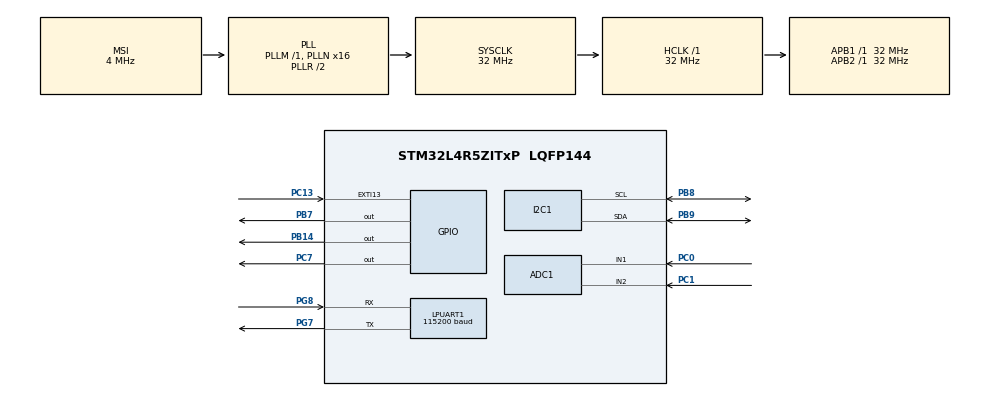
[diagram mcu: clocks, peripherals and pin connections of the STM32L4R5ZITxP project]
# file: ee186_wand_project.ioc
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ADC1.Channel-0\#ChannelRegularConversion=ADC_CHANNEL_1
ADC1.Channel-1\#ChannelRegularConversion=ADC_CHANNEL_2
ADC1.ContinuousConvMode=ENABLE
ADC1.DMAContinuousRequests=ENABLE
ADC1.NbrOfConversion=2
ADC1.NbrOfConversionFlag=1
ADC1.OffsetNumber-0\#ChannelRegularConversion=ADC_OFFSET_NONE
ADC1.OffsetNumber-1\#ChannelRegularConversion=ADC_OFFSET_NONE
ADC1.Rank-0\#ChannelRegularConversion=1
ADC1.Rank-1\#ChannelRegularConversion=2
ADC1.SamplingTime-0\#ChannelRegularConversion=ADC_SAMPLETIME_47CYCLES_5
ADC1.SamplingTime-1\#ChannelRegularConversion=ADC_SAMPLETIME_47CYCLES_5
ADC1.master=1
Dma.ADC1.0.Direction=DMA_PERIPH_TO_MEMORY
Dma.ADC1.0.EventEnable=DISABLE
Dma.ADC1.0.Instance=DMA1_Channel1
Dma.ADC1.0.MemDataAlignment=DMA_MDATAALIGN_HALFWORD
Dma.ADC1.0.MemInc=DMA_MINC_ENABLE
Dma.ADC1.0.Mode=DMA_CIRCULAR
Dma.ADC1.0.PeriphDataAlignment=DMA_PDATAALIGN_HALFWORD
Dma.ADC1.0.PeriphInc=DMA_PINC_DISABLE
Dma.ADC1.0.Polarity=HAL_DMAMUX_REQUEST_GEN_RISING
Dma.ADC1.0.Priority=DMA_PRIORITY_LOW
Dma.ADC1.0.RequestNumber=1
Dma.ADC1.0.SignalID=NONE
Dma.ADC1.0.SyncEnable=DISABLE
Dma.ADC1.0.SyncPolarity=HAL_DMAMUX_SYNC_NO_EVENT
Dma.ADC1.0.SyncRequestNumber=1
Dma.ADC1.0.SyncSignalID=NONE
Dma.Request0=ADC1
I2C1.Timing=0x00B07CB4
LPUART1.BaudRate=115200
LPUART1.WordLength=UART_WORDLENGTH_8B
Mcu.Family=STM32L4
Mcu.Name=STM32L4R5ZITxP
Mcu.Package=LQFP144
NVIC.DMA1_Channel1_IRQn=true\:0\:0\:false\:false\:true\:false\:true\:true
NVIC.EXTI15_10_IRQn=true\:0\:0\:true\:false\:true\:true\:true\:true
NVIC.PriorityGroup=NVIC_PRIORITYGROUP_4
NVIC.TIM4_IRQn=true\:0\:0\:false\:false\:true\:true\:true\:true
NVIC.TIM6_DAC_IRQn=true\:0\:0\:false\:false\:true\:true\:true\:true
PA13\ (JTMS/SWDIO).Mode=Serial_Wire
PA13\ (JTMS/SWDIO).Signal=SYS_JTMS-SWDIO
PA14\ (JTCK/SWCLK).Mode=Serial_Wire
PA14\ (JTCK/SWCLK).Signal=SYS_JTCK-SWCLK
PB14.Signal=GPIO_Output
PB7.Signal=GPIO_Output
PB8.Mode=I2C
PB8.Signal=I2C1_SCL
PB9.Mode=I2C
PB9.Signal=I2C1_SDA
PC0.Signal=ADCx_IN1
PC1.Signal=ADCx_IN2
PC13.Signal=GPXTI13
PC14-OSC32_IN\ (PC14).Mode=LSE-External-Oscillator
PC14-OSC32_IN\ (PC14).Signal=RCC_OSC32_IN
PC15-OSC32_OUT\ (PC15).Mode=LSE-External-Oscillator
PC15-OSC32_OUT\ (PC15).Signal=RCC_OSC32_OUT
PC7.Signal=GPIO_Output
PD14.Signal=S_TIM4_CH3
PD15.Signal=S_TIM4_CH4
PE0.Signal=S_TIM4_ETR
PG7.Mode=Asynchronous
PG7.Signal=LPUART1_TX
PG8.Mode=Asynchronous
PG8.Signal=LPUART1_RX
PH0-OSC_IN\ (PH0).Mode=HSE-External-Oscillator
PH0-OSC_IN\ (PH0).Signal=RCC_OSC_IN
PH1-OSC_OUT\ (PH1).Mode=HSE-External-Oscillator
PH1-OSC_OUT\ (PH1).Signal=RCC_OSC_OUT
ProjectManager.HeapSize=0x200
ProjectManager.StackSize=0x400
ProjectManager.TargetToolchain=STM32CubeIDE
RCC.ADCFreq_Value=48000000
RCC.AHBFreq_Value=32000000
RCC.APB1Freq_Value=32000000
RCC.APB1TimFreq_Value=32000000
RCC.APB2Freq_Value=32000000
RCC.APB2TimFreq_Value=32000000
RCC.CortexFreq_Value=32000000
RCC.HCLKFreq_Value=32000000
RCC.HSE_VALUE=8000000
RCC.HSI48_VALUE=48000000
RCC.HSI_VALUE=16000000
RCC.MSI_VALUE=4000000
RCC.PLLN=16
RCC.PLLSAI1N=24
RCC.SYSCLKFreq_VALUE=32000000
RCC.SYSCLKSource=RCC_SYSCLKSOURCE_PLLCLK
RCC.USBFreq_Value=48000000
RCC.VCOOutputFreq_Value=64000000
SH.ADCx_IN1.0=ADC1_IN1,IN1-Single-Ended
SH.ADCx_IN2.0=ADC1_IN2,IN2-Single-Ended
SH.S_TIM4_CH3.0=TIM4_CH3
SH.S_TIM4_CH4.0=TIM4_CH4
SH.S_TIM4_ETR.0=TIM4_ETR
TIM4.AutoReloadPreload=TIM_AUTORELOAD_PRELOAD_DISABLE
TIM4.Prescaler=31999
VP_TIM4_VS_ClockSourceINT.Mode=Internal
VP_TIM6_VS_ClockSourceINT.Mode=Enable_Timer
board=NUCLEO-L4R5ZI-P

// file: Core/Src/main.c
/* USER CODE BEGIN Header */
/**
  ******************************************************************************
  * @file           : main.c
  * @brief          : Main program body
  ******************************************************************************
  * @attention
  *
  * Copyright (c) 2026 STMicroelectronics.
  * All rights reserved.
  *
  * This software is licensed under terms that can be found in the LICENSE file
  * in the root directory of this software component.
  * If no LICENSE file comes with this software, it is provided AS-IS.
  *
  ******************************************************************************
  */
/* USER CODE END Header */
#include "main.h"

ADC_HandleTypeDef hadc1;
DMA_HandleTypeDef hdma_adc1;

I2C_HandleTypeDef hi2c1;

UART_HandleTypeDef hlpuart1;

TIM_HandleTypeDef htim4;
TIM_HandleTypeDef htim6;

void SystemClock_Config(void);
static void MX_GPIO_Init(void);
static void MX_DMA_Init(void);
static void MX_ADC1_Init(void);
static void MX_I2C1_Init(void);
static void MX_LPUART1_UART_Init(void);
static void MX_TIM4_Init(void);
static void MX_TIM6_Init(void);

int main(void)
{

  /* MCU Configuration--------------------------------------------------------*/

  /* Reset of all peripherals, Initializes the Flash interface and the Systick. */
  HAL_Init();

  /* Configure the system clock */
  SystemClock_Config();

  /* Initialize all configured peripherals */
  MX_GPIO_Init();
  MX_DMA_Init();
  MX_ADC1_Init();
  MX_I2C1_Init();
  MX_LPUART1_UART_Init();
  MX_TIM4_Init();
  MX_TIM6_Init();
  /* USER CODE BEGIN 2 */
  HAL_TIM_Base_Start_IT(&htim4); // start tim4 interrupt

  /* USER CODE END 2 */

  /* Infinite loop */
  while (1)
  {

  }
}

void SystemClock_Config(void)
{
  RCC_OscInitTypeDef RCC_OscInitStruct = {0};
  RCC_ClkInitTypeDef RCC_ClkInitStruct = {0};

  /** Configure the main internal regulator output voltage
  */
  if (HAL_PWREx_ControlVoltageScaling(PWR_REGULATOR_VOLTAGE_SCALE1) != HAL_OK)
  {
    Error_Handler();
  }

  /** Initializes the RCC Oscillators according to the specified parameters
  * in the RCC_OscInitTypeDef structure.
  */
  RCC_OscInitStruct.OscillatorType = RCC_OSCILLATORTYPE_MSI;
  RCC_OscInitStruct.MSIState = RCC_MSI_ON;
  RCC_OscInitStruct.MSICalibrationValue = 0;
  RCC_OscInitStruct.MSIClockRange = RCC_MSIRANGE_6;
  RCC_OscInitStruct.PLL.PLLState = RCC_PLL_ON;
  RCC_OscInitStruct.PLL.PLLSource = RCC_PLLSOURCE_MSI;
  RCC_OscInitStruct.PLL.PLLM = 1;
  RCC_OscInitStruct.PLL.PLLN = 16;
  RCC_OscInitStruct.PLL.PLLP = RCC_PLLP_DIV2;
  RCC_OscInitStruct.PLL.PLLQ = RCC_PLLQ_DIV2;
  RCC_OscInitStruct.PLL.PLLR = RCC_PLLR_DIV2;
  if (HAL_RCC_OscConfig(&RCC_OscInitStruct) != HAL_OK)
  {
    Error_Handler();
  }

  /** Initializes the CPU, AHB and APB buses clocks
  */
  RCC_ClkInitStruct.ClockType = RCC_CLOCKTYPE_HCLK|RCC_CLOCKTYPE_SYSCLK
                              |RCC_CLOCKTYPE_PCLK1|RCC_CLOCKTYPE_PCLK2;
  RCC_ClkInitStruct.SYSCLKSource = RCC_SYSCLKSOURCE_PLLCLK;
  RCC_ClkInitStruct.AHBCLKDivider = RCC_SYSCLK_DIV1;
  RCC_ClkInitStruct.APB1CLKDivider = RCC_HCLK_DIV1;
  RCC_ClkInitStruct.APB2CLKDivider = RCC_HCLK_DIV1;

  if (HAL_RCC_ClockConfig(&RCC_ClkInitStruct, FLASH_LATENCY_1) != HAL_OK)
  {
    Error_Handler();
  }
}

static void MX_ADC1_Init(void)
{

  ADC_ChannelConfTypeDef sConfig = {0};

  /** Common config
  */
  hadc1.Instance = ADC1;
  hadc1.Init.ClockPrescaler = ADC_CLOCK_ASYNC_DIV1;
  hadc1.Init.Resolution = ADC_RESOLUTION_12B;
  hadc1.Init.DataAlign = ADC_DATAALIGN_RIGHT;
  hadc1.Init.ScanConvMode = ADC_SCAN_ENABLE;
  hadc1.Init.EOCSelection = ADC_EOC_SINGLE_CONV;
  hadc1.Init.LowPowerAutoWait = DISABLE;
  hadc1.Init.ContinuousConvMode = ENABLE;
  hadc1.Init.NbrOfConversion = 2;
  hadc1.Init.DiscontinuousConvMode = DISABLE;
  hadc1.Init.ExternalTrigConv = ADC_SOFTWARE_START;
  hadc1.Init.ExternalTrigConvEdge = ADC_EXTERNALTRIGCONVEDGE_NONE;
  hadc1.Init.DMAContinuousRequests = ENABLE;
  hadc1.Init.Overrun = ADC_OVR_DATA_PRESERVED;
  hadc1.Init.OversamplingMode = DISABLE;
  if (HAL_ADC_Init(&hadc1) != HAL_OK)
  {
    Error_Handler();
  }

  /** Configure Regular Channel
  */
  sConfig.Channel = ADC_CHANNEL_1;
  sConfig.Rank = ADC_REGULAR_RANK_1;
  sConfig.SamplingTime = ADC_SAMPLETIME_47CYCLES_5;
  sConfig.SingleDiff = ADC_SINGLE_ENDED;
  sConfig.OffsetNumber = ADC_OFFSET_NONE;
  sConfig.Offset = 0;
  if (HAL_ADC_ConfigChannel(&hadc1, &sConfig) != HAL_OK)
  {
    Error_Handler();
  }

  /** Configure Regular Channel
  */
  sConfig.Channel = ADC_CHANNEL_2;
  sConfig.Rank = ADC_REGULAR_RANK_2;
  if (HAL_ADC_ConfigChannel(&hadc1, &sConfig) != HAL_OK)
  {
    Error_Handler();
  }

}

static void MX_I2C1_Init(void)
{

  hi2c1.Instance = I2C1;
  hi2c1.Init.Timing = 0x00B07CB4;
  hi2c1.Init.OwnAddress1 = 0;
  hi2c1.Init.AddressingMode = I2C_ADDRESSINGMODE_7BIT;
  hi2c1.Init.DualAddressMode = I2C_DUALADDRESS_DISABLE;
  hi2c1.Init.OwnAddress2 = 0;
  hi2c1.Init.OwnAddress2Masks = I2C_OA2_NOMASK;
  hi2c1.Init.GeneralCallMode = I2C_GENERALCALL_DISABLE;
  hi2c1.Init.NoStretchMode = I2C_NOSTRETCH_DISABLE;
  if (HAL_I2C_Init(&hi2c1) != HAL_OK)
  {
    Error_Handler();
  }

  /** Configure Analogue filter
  */
  if (HAL_I2CEx_ConfigAnalogFilter(&hi2c1, I2C_ANALOGFILTER_ENABLE) != HAL_OK)
  {
    Error_Handler();
  }

  /** Configure Digital filter
  */
  if (HAL_I2CEx_ConfigDigitalFilter(&hi2c1, 0) != HAL_OK)
  {
    Error_Handler();
  }

}

static void MX_LPUART1_UART_Init(void)
{

  hlpuart1.Instance = LPUART1;
  hlpuart1.Init.BaudRate = 115200;
  hlpuart1.Init.WordLength = UART_WORDLENGTH_8B;
  hlpuart1.Init.StopBits = UART_STOPBITS_1;
  hlpuart1.Init.Parity = UART_PARITY_NONE;
  hlpuart1.Init.Mode = UART_MODE_TX_RX;
  hlpuart1.Init.HwFlowCtl = UART_HWCONTROL_NONE;
  hlpuart1.Init.OneBitSampling = UART_ONE_BIT_SAMPLE_DISABLE;
  hlpuart1.Init.ClockPrescaler = UART_PRESCALER_DIV1;
  hlpuart1.AdvancedInit.AdvFeatureInit = UART_ADVFEATURE_NO_INIT;
  hlpuart1.FifoMode = UART_FIFOMODE_DISABLE;
  if (HAL_UART_Init(&hlpuart1) != HAL_OK)
  {
    Error_Handler();
  }
  if (HAL_UARTEx_SetTxFifoThreshold(&hlpuart1, UART_TXFIFO_THRESHOLD_1_8) != HAL_OK)
  {
    Error_Handler();
  }
  if (HAL_UARTEx_SetRxFifoThreshold(&hlpuart1, UART_RXFIFO_THRESHOLD_1_8) != HAL_OK)
  {
    Error_Handler();
  }
  if (HAL_UARTEx_DisableFifoMode(&hlpuart1) != HAL_OK)
  {
    Error_Handler();
  }

}

static void MX_TIM4_Init(void)
{

  TIM_ClockConfigTypeDef sClockSourceConfig = {0};
  TIM_MasterConfigTypeDef sMasterConfig = {0};

  htim4.Instance = TIM4;
  htim4.Init.Prescaler = 31999;
  htim4.Init.CounterMode = TIM_COUNTERMODE_UP;
  htim4.Init.Period = 65535;
  htim4.Init.ClockDivision = TIM_CLOCKDIVISION_DIV1;
  htim4.Init.AutoReloadPreload = TIM_AUTORELOAD_PRELOAD_DISABLE;
  if (HAL_TIM_Base_Init(&htim4) != HAL_OK)
  {
    Error_Handler();
  }
  sClockSourceConfig.ClockSource = TIM_CLOCKSOURCE_INTERNAL;
  if (HAL_TIM_ConfigClockSource(&htim4, &sClockSourceConfig) != HAL_OK)
  {
    Error_Handler();
  }
  sMasterConfig.MasterOutputTrigger = TIM_TRGO_RESET;
  sMasterConfig.MasterSlaveMode = TIM_MASTERSLAVEMODE_DISABLE;
  if (HAL_TIMEx_MasterConfigSynchronization(&htim4, &sMasterConfig) != HAL_OK)
  {
    Error_Handler();
  }

}

static void MX_TIM6_Init(void)
{

  TIM_MasterConfigTypeDef sMasterConfig = {0};

  htim6.Instance = TIM6;
  htim6.Init.Prescaler = 0;
  htim6.Init.CounterMode = TIM_COUNTERMODE_UP;
  htim6.Init.Period = 65535;
  htim6.Init.AutoReloadPreload = TIM_AUTORELOAD_PRELOAD_DISABLE;
  if (HAL_TIM_Base_Init(&htim6) != HAL_OK)
  {
    Error_Handler();
  }
  sMasterConfig.MasterOutputTrigger = TIM_TRGO_RESET;
  sMasterConfig.MasterSlaveMode = TIM_MASTERSLAVEMODE_DISABLE;
  if (HAL_TIMEx_MasterConfigSynchronization(&htim6, &sMasterConfig) != HAL_OK)
  {
    Error_Handler();
  }

}

static void MX_DMA_Init(void)
{

  /* DMA controller clock enable */
  __HAL_RCC_DMAMUX1_CLK_ENABLE();
  __HAL_RCC_DMA1_CLK_ENABLE();

  /* DMA interrupt init */
  /* DMA1_Channel1_IRQn interrupt configuration */
  HAL_NVIC_SetPriority(DMA1_Channel1_IRQn, 0, 0);
  HAL_NVIC_EnableIRQ(DMA1_Channel1_IRQn);

}

static void MX_GPIO_Init(void)
{
  GPIO_InitTypeDef GPIO_InitStruct = {0};

  /* GPIO Ports Clock Enable */
  __HAL_RCC_GPIOC_CLK_ENABLE();
  __HAL_RCC_GPIOH_CLK_ENABLE();
  __HAL_RCC_GPIOB_CLK_ENABLE();
  __HAL_RCC_GPIOD_CLK_ENABLE();
  __HAL_RCC_GPIOG_CLK_ENABLE();
  HAL_PWREx_EnableVddIO2();
  __HAL_RCC_GPIOA_CLK_ENABLE();
  __HAL_RCC_GPIOE_CLK_ENABLE();

  /*Configure GPIO pin Output Level */
  HAL_GPIO_WritePin(GPIOB, GPIO_PIN_14|GPIO_PIN_7, GPIO_PIN_RESET);

  /*Configure GPIO pin Output Level */
  HAL_GPIO_WritePin(GPIOC, GPIO_PIN_7, GPIO_PIN_RESET);

  /*Configure GPIO pin : PC13 */
  GPIO_InitStruct.Pin = GPIO_PIN_13;
  GPIO_InitStruct.Mode = GPIO_MODE_IT_RISING;
  GPIO_InitStruct.Pull = GPIO_NOPULL;
  HAL_GPIO_Init(GPIOC, &GPIO_InitStruct);

  /*Configure GPIO pins : PB14 PB7 */
  GPIO_InitStruct.Pin = GPIO_PIN_14|GPIO_PIN_7;
  GPIO_InitStruct.Mode = GPIO_MODE_OUTPUT_PP;
  GPIO_InitStruct.Pull = GPIO_NOPULL;
  GPIO_InitStruct.Speed = GPIO_SPEED_FREQ_LOW;
  HAL_GPIO_Init(GPIOB, &GPIO_InitStruct);

  /*Configure GPIO pin : PC7 */
  GPIO_InitStruct.Pin = GPIO_PIN_7;
  GPIO_InitStruct.Mode = GPIO_MODE_OUTPUT_PP;
  GPIO_InitStruct.Pull = GPIO_NOPULL;
  GPIO_InitStruct.Speed = GPIO_SPEED_FREQ_LOW;
  HAL_GPIO_Init(GPIOC, &GPIO_InitStruct);

  /* EXTI interrupt init*/
  HAL_NVIC_SetPriority(EXTI15_10_IRQn, 0, 0);
  HAL_NVIC_EnableIRQ(EXTI15_10_IRQn);

}

/* USER CODE BEGIN 4 */
void HAL_TIM_PeriodElapsedCallback(TIM_HandleTypeDef *htim)
{
    if (htim->Instance == TIM4)
    {
        HAL_GPIO_TogglePin(GPIOC, GPIO_PIN_7); // toggle green
    }
}
/* USER CODE END 4 */

void Error_Handler(void)
{
  __disable_irq();
  while (1)
  {
  }
}
